# STM32G554 register map
File version: 2.0.0
CPU: CM33 r0p4, little endian, MPU, FPU, 4 interrupt priority bits
Registers are 32-bit, read-write, reset 0x0 unless marked. A register's access mark holds for its fields unless they carry their own. Offsets are from the block's base; [hi:lo] are bit positions; {n}, {i} and the like mark numbered series; 'fields as' and 'values as' point back to an identical list.

## RCC (part 2 of 2) — RCC register block
Base 0x44020C00
Same registers: RCC_S 0x54020C00
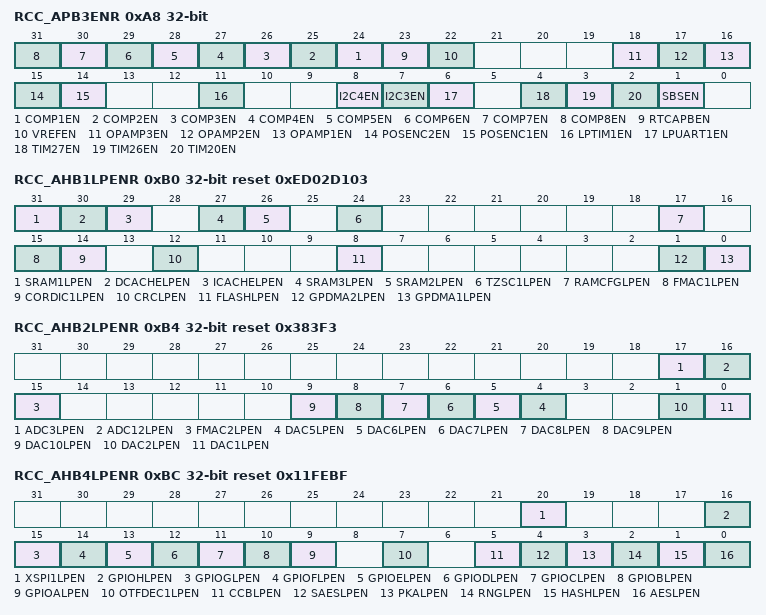
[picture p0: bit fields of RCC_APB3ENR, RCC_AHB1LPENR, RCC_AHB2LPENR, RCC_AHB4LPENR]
0xA8 RCC_APB3ENR — RCC APB3 peripheral clock enable register
  [n+23] COMP{n}EN (n=1..8) — COMP{n} clock enable
    0=COMP{n} clock disabled (default after reset); 1=COMP{n} clock enabled
  [23] RTCAPBEN — RTC APB interface clock enable
    0=RTC APB interface clock disabled (default after reset); 1=RTC APB interface clock enabled
  [22] VREFEN — VREFBUF clock enable
    0=VREFBUF peripheral clock disabled (default after reset); 1=VREFBUF peripheral clock enabled
  [18] OPAMP3EN — OPAMP3 clock enable
    0=OPAMP3 clock disabled (default after reset); 1=OPAMP3 clock enabled
  [17] OPAMP2EN — OPAMP2 clock enable
    0=OPAMP2 clock disabled (default after reset); 1=OPAMP2 clock enabled
  [16] OPAMP1EN — OPAMP1 clock enable
    0=OPAMP1 clock disabled (default after reset); 1=OPAMP1 clock enabled
  [15] POSENC2EN — POSENC2 clock enable
    0=POSENC2 clock disabled (default after reset); 1=POSENC2 clock enabled
  [14] POSENC1EN — POSENC1 clock enable
    0=POSENC1 clock disabled (default after reset); 1=POSENC1 clock enabled
  [11] LPTIM1EN — LPTIM1 clock enable
    0=LPTIM1 peripheral clock disabled (default after reset); 1=LPTIM1 peripheral clock enabled
  [8] I2C4EN — I2C4 clock enable
    0=I2C4 peripheral clock disabled (default after reset); 1=I2C4 peripheral clock enabled
  [7] I2C3EN — I2C3 clock enable
    0=I2C3 peripheral clock disabled (default after reset); 1=I2C3 peripheral clock enabled
  [6] LPUART1EN — LPUART1 clock enable
    0=LPUART1 peripheral clock disabled (default after reset); 1=LPUART1 peripheral clock enabled
  [4] TIM27EN — TIM27 clock enable
    0=TIM27 peripheral clock disabled (default after reset); 1=TIM27 peripheral clock enabled
  [3] TIM26EN — TIM26 clock enable
    0=TIM26 peripheral clock disabled (default after reset); 1=TIM26 peripheral clock enabled
  [2] TIM20EN — TIM20 clock enable
    0=TIM20 peripheral clock disabled (default after reset); 1=TIM20 peripheral clock enabled
  [1] SBSEN — SBS clock enable
    0=SBS peripheral clock disabled (default after reset); 1=SBS peripheral clock enabled
0xB0 RCC_AHB1LPENR reset 0xED02D103 — RCC AHB1 peripheral low-power clock enable register
  [31] SRAM1LPEN — SRAM1 clock enable in low-power mode
    0=SRAM1 clock disabled in low-power mode; 1=SRAM1 clock enabled in low-power mode (default after reset)
  [30] DCACHELPEN — DCACHE clock enable in low-power mode
    0=DCACHE peripheral clock disabled in low-power mode; 1=DCACHE peripheral clock enabled in low-power mode (default after reset)
  [29] ICACHELPEN — ICACHE clock enable in low-power mode
    0=ICACHE peripheral clock disabled in low-power mode; 1=ICACHE peripheral clock enabled in low-power mode (default after reset)
  [27] SRAM3LPEN — SRAM3 clock enable in low-power mode
    0=SRAM3 peripheral clock disabled in low-power mode; 1=SRAM3 peripheral clock enabled in low-power mode (default after reset)
  [26] SRAM2LPEN — SRAM2 clock enable in low-power mode
    0=SRAM2 peripheral clock disabled in low-power mode; 1=SRAM2 peripheral clock enabled in low-power mode (default after reset)
  [24] TZSC1LPEN — TZSC1 clock enable in low-power mode
    0=TZSC1 peripheral clock disabled in low-power mode; 1=TZSC1 peripheral clock enabled in low-power mode (default after reset)
  [17] RAMCFGLPEN — RAMCFG clock enable in low-power mode
    0=RAMCFG peripheral clock disabled in low-power mode; 1=RAMCFG peripheral clock enabled in low-power mode (default after reset)
  [15] FMAC1LPEN — FMAC1 clock enable in low-power mode
    0=FMAC1 peripheral clock disabled in low-power mode; 1=FMAC1 peripheral clock enabled in low-power mode (default after reset)
  [14] CORDIC1LPEN — CORDIC1 clock enable in low-power mode
    0=CORDIC1 peripheral clock disabled in low-power mode; 1=CORDIC1 peripheral clock enabled in low-power mode (default after reset)
  [12] CRCLPEN — CRC clock enable in low-power mode
    0=CRC peripheral clock disabled in low-power mode; 1=CRC peripheral clock enabled in low-power mode (default after reset)
  [8] FLASHLPEN — Flash memory interface clock enable in low-power mode
    0=Flash memory interface clock disabled in low-power mode; 1=Flash memory interface clock enabled in low-power mode (default after reset)
  [1] GPDMA2LPEN — GPDMA2 clock enable in low-power mode
    0=GPDMA2 peripheral clock disabled in low-power mode; 1=GPDMA2 peripheral clock enabled in low-power mode (default after reset)
  [0] GPDMA1LPEN — GPDMA1 clock enable in low-power mode
    0=GPDMA1 peripheral clock disabled in low-power mode; 1=GPDMA1 peripheral clock enabled in low-power mode (default after reset)
0xB4 RCC_AHB2LPENR reset 0x383F3 — RCC AHB2 peripheral low-power clock enable register
  [17] ADC3LPEN — ADC3 peripheral clock enable in low-power mode
    0=ADC3 peripheral clocks disabled in low-power mode; 1=ADC3 peripheral clocks enabled in low-power mode (default after reset)
  [16] ADC12LPEN — ADC1 and 2 peripheral clock enable in low-power mode
    0=ADC1 and 2 peripheral clock disabled in low-power mode; 1=ADC1 and 2 peripheral clock enabled in low-power mode (default after reset)
  [15] FMAC2LPEN — FMAC2 clock enable in low-power mode
    0=FMAC2 peripheral clock disabled in low-power mode; 1=FMAC2 peripheral clock enabled in low-power mode (default after reset)
  [n-1] DAC{n}LPEN (n=5..10) — DAC{n} clock enable in low-power mode
    0=DAC{n} peripheral clock disabled in low-power mode; 1=DAC{n} peripheral clock enabled in low-power mode (default after reset)
  [1] DAC2LPEN — DAC2 clock enable in low-power mode
    0=DAC2 peripheral clock disabled in low-power mode; 1=DAC2 peripheral clock enabled in low-power mode (default after reset)
  [0] DAC1LPEN — DAC1 clock enable in low-power mode
    0=DAC1 peripheral clock disabled in low-power mode; 1=DAC1 peripheral clock enabled in low-power mode (default after reset)
0xB8 RCC_AHB3LPENR reset 0x200000 — RCC AHB3 peripheral low-power clock enable register
  [21] DBGCKLPEN — DBG clock enable in low-power mode
    0=DBG clock disabled in low-power mode; 1=DBG clock enabled in low-power mode (default after reset)
0xBC RCC_AHB4LPENR reset 0x11FEBF — RCC AHB4 peripheral low-power clock enable register
  [20] XSPI1LPEN — XSPI1 clock enable in low-power mode
    0=XSPI1 peripheral clock disabled in low-power mode; 1=XSPI1 peripheral clock enabled in low-power mode (default after reset)
  [16] GPIOHLPEN — GPIOH clock enable in low-power mode
    0=GPIOH peripheral clock disabled in low-power mode; 1=GPIOH peripheral clock enabled in low-power mode (default after reset)
  [15] GPIOGLPEN — GPIOG clock enable in low-power mode
    0=GPIOG peripheral clock disabled in low-power mode; 1=GPIOG peripheral clock enabled in low-power mode (default after reset)
  [14] GPIOFLPEN — GPIOF clock enable in low-power mode
    0=GPIOF peripheral clock disabled in low-power mode; 1=GPIOF peripheral clock enabled in low-power mode (default after reset)
  [13] GPIOELPEN — GPIOE clock enable in low-power mode
    0=GPIOE peripheral clock disabled in low-power mode; 1=GPIOE peripheral clock enabled in low-power mode (default after reset)
  [12] GPIODLPEN — GPIOD clock enable in low-power mode
    0=GPIOD peripheral clock disabled in low-power mode; 1=GPIOD peripheral clock enabled in low-power mode (default after reset)
  [11] GPIOCLPEN — GPIOC clock enable in low-power mode
    0=GPIOC peripheral clock disabled in low-power mode; 1=GPIOC peripheral clock enabled in low-power mode (default after reset)
  [10] GPIOBLPEN — GPIOB clock enable in low-power mode
    0=GPIOB peripheral clock disabled in low-power mode; 1=GPIOB peripheral clock enabled in low-power mode (default after reset)
  [9] GPIOALPEN — GPIOA clock enable in low-power mode
    0=GPIOA peripheral clock disabled in low-power mode; 1=GPIOA peripheral clock enabled in low-power mode (default after reset)
  [7] OTFDEC1LPEN — OTFDEC1 clock enable in low-power mode
    0=OTFDEC1 peripheral clock disabled in low-power mode; 1=OTFDEC1 peripheral clock enabled in low-power mode (default after reset)
  [5] CCBLPEN — CCB clock enable in low-power mode
    0=CCB peripheral clock disabled in low-power mode; 1=CCB peripheral clock enabled in low-power mode (default after reset)
  [4] SAESLPEN — SAES clock enable in low-power mode
    0=SAES peripheral clock disabled in low-power mode; 1=SAES peripheral clock enabled in low-power mode (default after reset)
  [3] PKALPEN — PKA clock enable in low-power mode
    0=PKA peripheral clock disabled in low-power mode; 1=PKA peripheral clock enabled in low-power mode (default after reset)
  [2] RNGLPEN — RNG clock enable in low-power mode
    0=RNG peripheral clock disabled in low-power mode; 1=RNG peripheral clock enabled in low-power mode (default after reset)
  [1] HASHLPEN — HASH clock enable in low-power mode
    0=HASH peripheral clock disabled in low-power mode; 1=HASH peripheral clock enabled in low-power mode (default after reset)
  [0] AESLPEN — AES clock enable in low-power mode
    0=AES peripheral clock disabled in low-power mode; 1=AES peripheral clock enabled in low-power mode (default after reset)
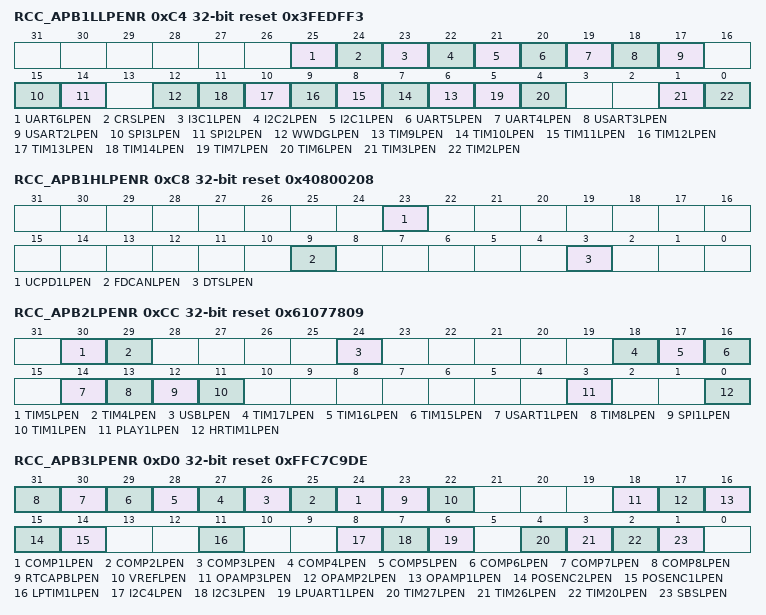
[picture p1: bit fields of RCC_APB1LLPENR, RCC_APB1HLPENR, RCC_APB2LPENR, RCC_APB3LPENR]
0xC4 RCC_APB1LLPENR reset 0x3FEDFF3 — RCC APB1 peripheral low-power clock enable register
  [25] UART6LPEN — UART6 clock enable in low-power mode
    0=UART6 peripheral clock disabled in low-power mode; 1=UART6 peripheral clock enabled in low-power mode (default after reset)
  [24] CRSLPEN — CRS clock enable in low-power mode
    0=CRS peripheral clock disabled in low-power mode; 1=CRS peripheral clock enabled in low-power mode (default after reset)
  [23] I3C1LPEN — I3C1 clock enable in low-power mode
    0=I3C1 peripheral clock disabled in low-power mode; 1=I3C1 peripheral clock enabled in low-power mode (default after reset)
  [22] I2C2LPEN — I2C2 clock enable in low-power mode
    0=I2C2 peripheral clock disabled in low-power mode; 1=I2C2 peripheral clock enabled in low-power mode (default after reset)
  [21] I2C1LPEN — I2C1 clock enable in low-power mode
    0=I2C1 peripheral clock disabled in low-power mode; 1=I2C1 peripheral clock enabled in low-power mode (default after reset)
  [20] UART5LPEN — UART5 clock enable in low-power mode
    0=UART5 peripheral clock disabled in low-power mode; 1=UART5 peripheral clock enabled in low-power mode (default after reset)
  [19] UART4LPEN — UART4 clock enable in low-power mode
    0=UART4 peripheral clock disabled in low-power mode; 1=UART4 peripheral clock enabled in low-power mode (default after reset)
  [18] USART3LPEN — USART3 clock enable in low-power mode
    0=USART3 peripheral clock disabled in low-power mode; 1=USART3 peripheral clock enabled in low-power mode (default after reset)
  [17] USART2LPEN — USART2 clock enable in low-power mode
    0=USART2 peripheral clock disabled in low-power mode; 1=USART2 peripheral clock enabled in low-power mode (default after reset)
  [15] SPI3LPEN — SPI3 clock enable in low-power mode
    0=SPI3 peripheral clock disabled in low-power mode; 1=SPI3 peripheral clock enabled in low-power mode (default after reset)
  [14] SPI2LPEN — SPI2 clock enable in low-power mode
    0=SPI2 peripheral clock disabled in low-power mode; 1=SPI2 peripheral clock enabled in low-power mode (default after reset)
  [12] WWDGLPEN — WWDG clock enable in low-power mode
    0=WWDG peripheral clock disabled in low-power mode; 1=WWDG peripheral clock enabled in low-power mode (default after reset)
  [n-3] TIM{n}LPEN (n=9..14) — TIM{n} clock enable in low-power mode
    0=TIM{n} peripheral clock disabled in low-power mode; 1=TIM{n} peripheral clock enabled in low-power mode (default after reset)
  [5] TIM7LPEN — TIM7 clock enable in low-power mode
    0=TIM7 peripheral clock disabled in low-power mode; 1=TIM7 peripheral clock enabled in low-power mode (default after reset)
  [4] TIM6LPEN — TIM6 clock enable in low-power mode
    0=TIM6 peripheral clock disabled in low-power mode; 1=TIM6 peripheral clock enabled in low-power mode (default after reset)
  [1] TIM3LPEN — TIM3 clock enable in low-power mode
    0=TIM3 peripheral clock disabled in low-power mode; 1=TIM3 peripheral clock enabled in low-power mode (default after reset)
  [0] TIM2LPEN — TIM2 clock enable in low-power mode
    0=TIM2 peripheral clock disabled in low-power mode; 1=TIM2 peripheral clock enabled in low-power mode (default after reset)
0xC8 RCC_APB1HLPENR reset 0x40800208 — RCC APB1 peripheral low-power clock enable register
  [23] UCPD1LPEN — UCPD1 clock enable in low-power mode
    0=UCPD1 peripheral clock disabled in low-power mode; 1=UCPD1 peripheral clock enabled in low-power mode (default after reset)
  [9] FDCANLPEN — FDCAN1, FDCAN2 and FDCAN3 peripheral clock enable in low-power mode
    0=FDCAN1, FDCAN2 and FDCAN3 peripheral clock disabled in low-power mode; 1=FDCAN1, FDCAN2 and FDCAN3 peripheral clock enabled in low-power mode (default after reset)
  [3] DTSLPEN — DTS clock enable in low-power mode
    0=DTS peripheral clock disabled in low-power mode; 1=DTS peripheral clock enabled in low-power mode (default after reset)
0xCC RCC_APB2LPENR reset 0x61077809 — RCC APB2 peripheral low-power clock enable register
  [30] TIM5LPEN — TIM5 clock enable in low-power mode
    0=TIM5 peripheral clock disabled in low-power mode; 1=TIM5 peripheral clock enabled in low-power mode (default after reset)
  [29] TIM4LPEN — TIM4 clock enable in low-power mode
    0=TIM4 peripheral clock disabled in low-power mode; 1=TIM4 peripheral clock enabled in low-power mode (default after reset)
  [24] USBLPEN — USB clock enable in low-power mode
    0=USB peripheral clock disabled in low-power mode; 1=USB peripheral clock enabled in low-power mode (default after reset)
  [18] TIM17LPEN — TIM17 clock enable in low-power mode
    0=TIM17 peripheral clock disabled in low-power mode; 1=TIM17 peripheral clock enabled in low-power mode (default after reset)
  [17] TIM16LPEN — TIM16 clock enable in low-power mode
    0=TIM16 peripheral clock disabled in low-power mode; 1=TIM16 peripheral clock enabled in low-power mode (default after reset)
  [16] TIM15LPEN — TIM15 clock enable in low-power mode
    0=TIM15 peripheral clock disabled in low-power mode; 1=TIM15 peripheral clock enabled in low-power mode (default after reset)
  [14] USART1LPEN — USART1 clock enable in low-power mode
    0=USART1 peripheral clock disabled in low-power mode; 1=USART1 peripheral clock enabled in low-power mode (default after reset)
  [13] TIM8LPEN — TIM8 clock enable in low-power mode
    0=TIM8 peripheral clock disabled in low-power mode; 1=TIM8 peripheral clock enabled in low-power mode (default after reset)
  [12] SPI1LPEN — SPI1 clock enable in low-power mode
    0=SPI1 peripheral clock disabled in low-power mode; 1=SPI1 peripheral clock enabled in low-power mode (default after reset)
  [11] TIM1LPEN — TIM1 clock enable in low-power mode
    0=TIM1 peripheral clock disabled in low-power mode; 1=TIM1 peripheral clock enabled in low-power mode (default after reset)
  [3] PLAY1LPEN — PLAY1 clock enable in low-power mode
    0=PLAY1 peripheral clock disabled in low-power mode; 1=PLAY1 peripheral clock enabled in low-power mode (default after reset)
  [0] HRTIM1LPEN — HRTIM1 clock enable in low-power mode
    0=HRTIM1 peripheral clock disabled in low-power mode; 1=HRTIM1 peripheral clock enabled in low-power mode (default after reset)
0xD0 RCC_APB3LPENR reset 0xFFC7C9DE — RCC APB3 peripheral low-power clock enable register
  [n+23] COMP{n}LPEN (n=1..8) — COMP{n} clock enable in low-power mode
    0=COMP{n} peripheral clock disabled in low-power mode; 1=COMP{n} peripheral clock enabled in low-power mode (default after reset)
  [23] RTCAPBLPEN — RTC APB interface clock enable in low-power mode
    0=RTC APB interface clock disabled in low-power mode; 1=RTC APB interface clock enabled in low-power mode (default after reset)
  [22] VREFLPEN — VREFBUF clock enable in low-power mode
    0=VREFBUF peripheral clock disabled in low-power mode; 1=VREFBUF peripheral clock enabled in low-power mode (default after reset)
  [18] OPAMP3LPEN — OPAMP3 clock enable in low-power mode
    0=OPAMP3 peripheral clock disabled in low-power mode; 1=OPAMP3 peripheral clock enabled in low-power mode (default after reset)
  [17] OPAMP2LPEN — OPAMP2 clock enable in low-power mode
    0=OPAMP2 peripheral clock disabled in low-power mode; 1=OPAMP2 peripheral clock enabled in low-power mode (default after reset)
  [16] OPAMP1LPEN — OPAMP1 clock enable in low-power mode
    0=OPAMP1 peripheral clock disabled in low-power mode; 1=OPAMP1 peripheral clock enabled in low-power mode (default after reset)
  [15] POSENC2LPEN — POSENC2 clock enable in low-power mode
    0=POSENC2 peripheral clock disabled in low-power mode; 1=POSENC2 peripheral clock enabled in low-power mode (default after reset)
  [14] POSENC1LPEN — POSENC1 clock enable in low-power mode
    0=POSENC1 peripheral clock disabled in low-power mode; 1=POSENC1 peripheral clock enabled in low-power mode (default after reset)
  [11] LPTIM1LPEN — LPTIM1 clock enable in low-power mode
    0=LPTIM1 peripheral clock disabled in low-power mode; 1=LPTIM1 peripheral clock enabled in low-power mode (default after reset)
  [8] I2C4LPEN — I2C4 clock enable in low-power mode
    0=I2C4 peripheral clock disabled in low-power mode; 1=I2C4 peripheral clock enabled in low-power mode (default after reset)
  [7] I2C3LPEN — I2C3 clock enable in low-power mode
    0=I2C3 peripheral clock disabled in low-power mode; 1=I2C3 peripheral clock enabled in low-power mode (default after reset)
  [6] LPUART1LPEN — LPUART1 clock enable in low-power mode
    0=LPUART1 peripheral clock disabled in low-power mode; 1=LPUART1 peripheral clock enabled in low-power mode (default after reset)
  [4] TIM27LPEN — TIM27 clock enable in low-power mode
    0=TIM27 peripheral clock disabled in low-power mode; 1=TIM27 peripheral clock enabled in low-power mode (default after reset)
  [3] TIM26LPEN — TIM26 clock enable in low-power mode
    0=TIM26 peripheral clock disabled in low-power mode; 1=TIM26 peripheral clock enabled in low-power mode (default after reset)
  [2] TIM20LPEN — TIM20 clock enable in low-power mode
    0=TIM20 peripheral clock disabled in low-power mode; 1=TIM20 peripheral clock enabled in low-power mode (default after reset)
  [1] SBSLPEN — SBS clock enable in low-power mode
    0=SBS peripheral clock disabled in low-power mode; 1=SBS peripheral clock enabled in low-power mode (default after reset)
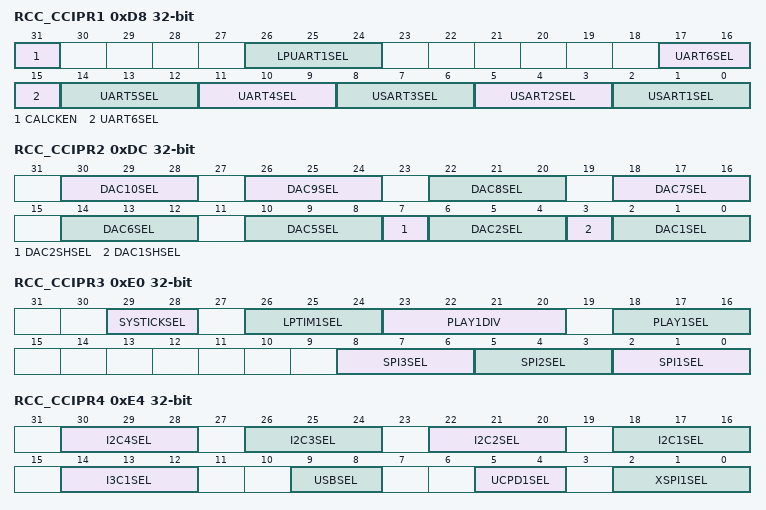
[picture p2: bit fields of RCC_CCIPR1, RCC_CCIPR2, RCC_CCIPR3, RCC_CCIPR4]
0xD8 RCC_CCIPR1 — RCC kernel clock configuration register
  [31] CALCKEN — Calibration clock enable
    0=Calibration clock (hsi_cal_ck) disabled (default after reset); 1=Calibration clock (hsi_cal_ck) enabled
  [26:24] LPUART1SEL — LPUART1 kernel clock source selection
    0=rcc_pclk3 s elected as kernel clock (default after reset); 1=ic1_ck selected as kernel clock; 2=pll2_q_ck selected as kernel clock (1); 3=hse_ker_ck selected as kernel clock; 4=hsi_ker_ck selected as kernel clock; 5=lse_ck selected as kernel clock
  [17:15] UART6SEL — UART6 kernel clock source selection
    0=rcc_pclk1 selected as kernel clock (default after reset); 1=ic1_ck selected as kernel clock; 2=pll2_q_ck selected as kernel clock (1); 3=hse_ker_ck selected as kernel clock; 4=hsi_ker_ck selected as kernel clock; 5=lse_ck selected as kernel clock
  [14:12] UART5SEL — UART5 kernel clock source selection
    values as UART6SEL
  [11:9] UART4SEL — UART4 kernel clock source selection
    values as UART6SEL
  [8:6] USART3SEL — USART3 kernel clock source selection
    values as UART6SEL
  [5:3] USART2SEL — USART2 kernel clock source selection
    values as UART6SEL
  [2:0] USART1SEL — USART1 kernel clock source selection
    0=rcc_pclk2 selected as kernel clock (default after reset); 1=ic1_ck selected as kernel clock; 2=pll2_q_ck selected as kernel clock; 3=hse_ker_ck selected as kernel clock; 4=hsi_ker_ck selected as kernel clock; 5=lse_ck selected as kernel clock
0xDC RCC_CCIPR2 — RCC kernel clock configuration register
  [30:28] DAC10SEL — DAC10 kernel clock source selection
    0=bus_ck (same as rcc_tim_ker_ck) selected as kernel clock (default after reset); 1=rcc_hrtim_ker_ck selected as kernel clock; 2=rcc_adc_ker_ck selected as kernel clock; 3=hse_ker_ck selected as kernel clock; 4=hsi_ker_ck selected as kernel clock; 5=pll1_q_ck selected as kernel clock; 6=pll2_q_ck selected as kernel clock
  [4n-10:4n-12] DAC{n}SEL (n=6..9) — DAC{n} kernel clock source selection
    0=bus_ck (same as rcc_tim_ker_ck) selected as kernel clock (default after reset); 1=rcc_hrtim_ker_ck selected as kernel clock; 2=rcc_adc_ker_ck selected as kernel clock; 3=hse_ker_ck selected as kernel clock; 4=hsi_ker_ck selected as kernel clock; 5=pll1_q_ck selected as kernel clock; 6=pll2_q_ck selected as kernel clock (1)
  [10:8] DAC5SEL — DAC5 kernel clock source selection
    0=bus_ck (same as rcc_tim_ker_ck) selected as kernel clock (default after reset); 1=rcc_hrtim_ker_ck selected as kernel clock; 2=rcc_adc_ker_ck selected as kernel clock; 3=hse_ker_ck selected as kernel clock; 4=hsi_ker_ck selected as kernel clock; 5=pll1_q_ck selected as kernel clock; 6=pll2_q_ck selected as kernel clock less thansup>(1)
  [7] DAC2SHSEL — DAC2 sample and hold clock
    0=lse_ck selected as kernel clock (default after reset); 1=lsi_ck selected as kernel clock
  [6:4] DAC2SEL — DAC2 kernel clock source selection
    values as DAC6SEL
  [3] DAC1SHSEL — DAC1 sample and hold clock
    values as DAC2SHSEL
  [2:0] DAC1SEL — DAC1 kernel clock source selection
    values as DAC6SEL
0xE0 RCC_CCIPR3 — RCC kernel clock configuration register
  [29:28] SYSTICKSEL — SYSTICK clock source selection
    0=rcc_hclk/8 selected as clock source (default after reset); 1=lsi_ck selected as clock source; 2=lse_ck selected as clock source
  [26:24] LPTIM1SEL — LPTIM1 kernel clock source selection
    0=rcc_pclk3 selected as kernel clock (default after reset); 1=pll1_q_ck selected as kernel clock; 2=pll2_p_ck selected as kernel clock; 3=hse_ker_ck selected as kernel clock; 4=hsi_ker_ck selected as kernel clock; 5=lsi_ck selected as kernel clock; 6=lse_ck selected as kernel clock
  [23:20] PLAY1DIV — PLAY1 kernel clock divider
    0=Selected kernel is not divided (default after reset); 1=Selected kernel clock is divided by 2; 2=Selected kernel clock is divided by 4; 3=Selected kernel clock is divided by 8; 4=Selected kernel clock is divided by 16; 5=Selected kernel clock is divided by 32; 6=Selected kernel clock is divided by 64; 7=Selected kernel clock is divided by 128; 8=Selected kernel clock is divided by 256; 9=Selected kernel clock is divided by 512; 10=Selected kernel clock is divided by 1024; 11=Selected kernel clock is divided by 2048; 12=Selected kernel clock is divided by 4096; 13=Selected kernel clock is divided by 8192; 14=Selected kernel clock is divided by 16384; 15=Selected kernel clock is divided by 32768
  [18:16] PLAY1SEL — PLAY1 kernel clock source selection
    0=lse_ck selected as kernel clock (default after reset); 1=lsi_ck selected as kernel clock; 2=pll2_p_ck selected as kernel clock (1); 3=hse_ker_ck selected as kernel clock; 4=hsi_ker_ck selected as kernel clock; 5=hsi48_ker_ck selected as kernel clock (1)
  [8:6] SPI3SEL — SPI3 kernel clock source selection
    0=rcc_pclk1 selected as kernel clock (default after reset); 1=ic1_ck selected as kernel clock; 2=pll2_p_ck selected as kernel clock (1); 3=hse_ker_ck selected as kernel clock; 4=hsi_ker_ck selected as kernel clock
  [5:3] SPI2SEL — SPI2 kernel clock source selection
    0=rcc_pclk1 selected as kernel clock (default after reset); 1=ic1_ck selected as kernel clock; 2=pll2_p_ck selected as kernel clock (1); 3=hse_ker_ck selected as kernel clock; 4=hsi_ker_ck selected as kernel clock; 5=AUDIOCLK selected as kernel clock
  [2:0] SPI1SEL — SPI1 kernel clock source selection
    0=rcc_pclk2 selected as kernel clock (default after reset); 1=ic1_ck selected as kernel clock; 2=pll2_p_ck selected as kernel clock (1); 3=hse_ker_ck selected as kernel clock; 4=hsi_ker_ck selected as kernel clock; 5=AUDIOCLK selected as kernel clock
0xE4 RCC_CCIPR4 — RCC kernel clock configuration register
  [30:28] I2C4SEL — I2C4 kernel clock source selection
    0=rcc_pclk3 selected as kernel clock (default after reset); 1=ic1_ck selected as kernel clock; 2=hsi_ker_ck selected as kernel clock; 3=hse_ker_ck selected as kernel clock; 4=hsi48_ker_ck selected as kernel clock
  [26:24] I2C3SEL — I2C3 kernel clock source selection
    values as I2C4SEL
  [22:20] I2C2SEL — I2C2 kernel clock source selection
    0=rcc_pclk1 selected as kernel clock (default after reset); 1=ic1_ck selected as kernel clock; 2=hsi_ker_ck selected as kernel clock; 3=hse_ker_ck selected as kernel clock
  [18:16] I2C1SEL — I2C1 kernel clock source selection
    values as I2C2SEL
  [14:12] I3C1SEL — I3C1 kernel clock source selection
    values as I2C2SEL
  [9:8] USBSEL — USB kernel clock source selection
    0=hsi48_ker_ck selected as kernel clock (default after reset); 1=hse_ker_ck selected as kernel clock; 2=pll1_q_ck selected as kernel clock; 3=pll2_q_ck selected as kernel clock
  [5:4] UCPD1SEL — UCPD1 clock source selection
    0=hsi_ker_ck selected as kernel clock (default after reset); 1=hse_ker_ck selected as kernel clock; 2=hsi48_ker_ck selected as kernel clock; 3=pll2_q_ck selected as kernel clock
  [2:0] XSPI1SEL — XSPI1 kernel clock source selection
    0=rcc_hclk4 selected as kernel clock (default after reset); 1=pll1_q_ck selected as kernel clock; 2=ic2_ck selected as kernel clock; 3=hse_ker_ck selected as kernel clock; 4=hsi_ker_ck selected as kernel clock
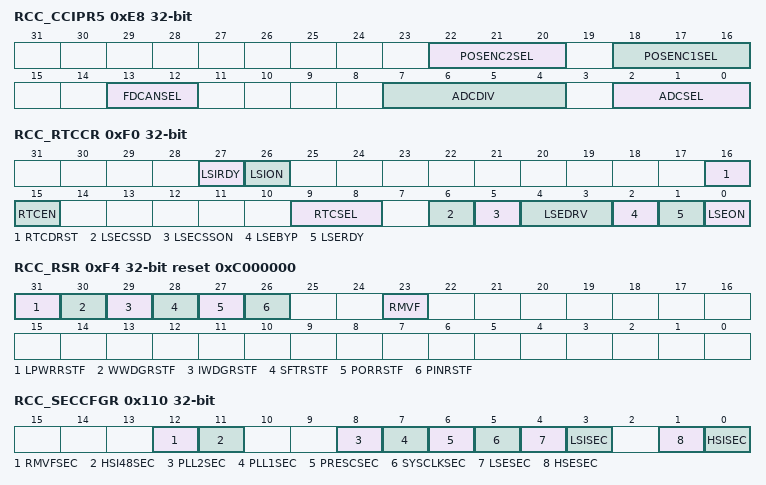
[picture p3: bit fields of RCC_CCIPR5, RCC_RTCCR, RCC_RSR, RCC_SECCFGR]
0xE8 RCC_CCIPR5 — RCC kernel clock configuration register
  [22:20] POSENC2SEL — POSENC2 kernel clock source selection
    0=pll1_p_ck selected as kernel clock (default after reset); 1=pll1_q_ck selected as kernel clock; 2=ic1_ck selected as kernel clock; 3=pll2_p_ck selected as kernel clock; 4=pll2_q_ck selected as kernel clock; 5=ic2_ck selected as kernel clock
  [18:16] POSENC1SEL — POSENC1 kernel clock source selection
    values as POSENC2SEL
  [13:12] FDCANSEL — FDCAN1, FDCAN2, and FDCAN3 kernel clock source selection
    0=hse_ker_ck selected as kernel clock (default after reset); 1=pll1_q_ck selected as kernel clock; 2=pll2_q_ck selected as kernel clock (1)
  [7:4] ADCDIV — ADC clock prescaler
    0=ADC kernel clock not divided (default after reset); 1=ADC kernel clock divided by 2; 2=ADC kernel clock divided by 4; 3=ADC kernel clock divided by 6; 4=ADC kernel clock divided by 8; 5=ADC kernel clock divided by 10; 6=ADC kernel clock divided by 12; 7=ADC kernel clock divided by 16; 8=ADC kernel clock divided by 32; 9=ADC kernel clock divided by 64; 10=ADC kernel clock divided by 128; 11=ADC kernel clock divided by 256
  [2:0] ADCSEL — ADC12 and ADC3 kernel clock source selection
    0=bus_ck (same as rcc_tim_ker_ck) selected as kernel clock (default after reset); 1=rcc_hrtim_ker_ck selected as kernel clock; 2=hsi_ker_ck selected as kernel clock; 3=hse_ker_ck selected as kernel clock; 4=pll1_q_ck selected as kernel clock; 5=ic1_ck selected as kernel clock; 6=pll2_p_ck selected as kernel clock; 7=ic2_ck selected as kernel clock (1)
0xF0 RCC_RTCCR rw-once — RCC RTC domain control register
  [27] LSIRDY ro — LSI oscillator ready
    0=LSI oscillator not ready (default after power-on reset); 1=LSI oscillator ready
  [26] LSION rw — LSI oscillator enable
    0=LSI oscillator off (default after power-on reset); 1=LSI oscillator on
  [16] RTCDRST rw — RTC domain software reset
    0=reset not activated (default after RTC domain reset); 1=resets the entire RTC domain
  [15] RTCEN rw — RTC clock enable
    0=rtc_ck disabled (default after RTC domain reset); 1=rtc_ck enabled
  [9:8] RTCSEL — RTC clock source selection
    0=no clock (default after RTC domain reset); 1=LSE selected as RTC clock; 2=LSI selected as RTC clock; 3=HSE divided by RTCPRE value selected as RTC clock
  [6] LSECSSD ro — LSE clock security system failure detection
    0=no failure detected on 32kHz oscillator (default after VDD domain reset); 1=failure detected on 32kHz oscillator
  [5] LSECSSON rw — LSE clock security system enable
    0=CSS on LSE oscillator OFF (default after VDD domain reset); 1=CSS on LSE oscillator ON
  [4:3] LSEDRV rw — LSE oscillator driving capability
    2=medium-high drive; 3=highest drive
  [2] LSEBYP rw — LSE oscillator bypass
    0=LSE oscillator not bypassed (default after VDD domain reset); 1=LSE oscillator bypassed
  [1] LSERDY ro — LSE oscillator ready
    0=LSE oscillator not ready (default after VDD domain reset); 1=LSE oscillator ready
  [0] LSEON rw — LSE oscillator enabled
    0=LSE oscillator OFF (default after VDD domain reset); 1=LSE oscillator ON
0xF4 RCC_RSR reset 0xC000000 — RCC reset status register
  [31] LPWRRSTF ro — Low-power reset flag
    0=No illegal low-power mode reset occurred; 1=Illegal low-power mode reset occurred
  [30] WWDGRSTF ro — window watchdog reset flag
    0=no window watchdog reset occurred from WWDG (default after power-on reset); 1=window watchdog reset occurred from WWDG
  [29] IWDGRSTF ro — independent watchdog reset flag
    0=no independent watchdog reset occurred (default after power-on reset); 1=independent watchdog reset occurred
  [28] SFTRSTF ro — system reset from CPU reset flag
    0=no CPU software reset occurred (default after power-on reset); 1=a system reset has been generated by the CPU
  [27] PORRSTF ro — POR reset flag
    0=no POR reset occurred; 1=POR reset occurred (default after power-on reset)
  [26] PINRSTF ro — pin reset flag (NRST)
    0=no reset from pin occurred; 1=reset from pin occurred (default after power-on reset)
  [23] RMVF wo — remove reset flag
    0=reset of the reset flags not activated (default after power-on reset); 1=resets the value of the reset flags
0x110 RCC_SECCFGR — RCC secure configuration register
  [all] fields
    0=nonsecure; 1=secure
  [12] RMVFSEC — Remove reset flag security
  [11] HSI48SEC — HSI48 clock configuration and status bits security
  [8] PLL2SEC — PLL2 clock configuration and status bits security
  [7] PLL1SEC — PLL1 clock configuration and status bits security
  [6] PRESCSEC — AHBx/APBx prescaler configuration bits security
  [5] SYSCLKSEC — SYSCLK clock selection, clock output on MCO configuration security
  [4] LSESEC — LSE clock configuration and status bits security
  [3] LSISEC — LSI clock configuration and status bits security
  [1] HSESEC — HSE clock configuration bits, status bits and HSE_CSS security
  [0] HSISEC — HSI clock configuration and status bits security
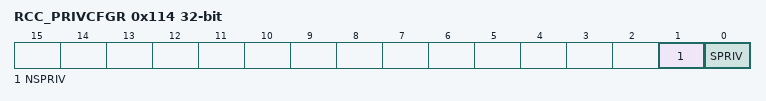
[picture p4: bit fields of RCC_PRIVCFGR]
0x114 RCC_PRIVCFGR — RCC privilege configuration register
  [1] NSPRIV — RCC nonsecure functions privilege configuration
    0=Read and write to RCC nonsecure functions can be done by privileged or unprivileged access; 1=Read and write to RCC nonsecure functions can be done by privileged access only
  [0] SPRIV — RCC secure functions privilege configuration
    0=Read and write to RCC secure functions can be done by privileged or unprivileged access; 1=Read and write to RCC secure functions can be done by privileged access only
